# BL616/BL618 register map
Vendor: Bouffalo Lab; File version: 1.0
Registers are 32-bit, read-write, reset 0x0 unless marked. A register's access mark holds for its fields unless they carry their own. Offsets are from the block's base; [hi:lo] are bit positions; lines under a group give offsets from that group; {n}, {i} and the like mark numbered series.

## DMA — Direct Memory Access module
Base 0x2000C000
0x00 interrupt_state — ??
0x04 terminate_state — ??
0x08 terminate_clear — ??
0x0C error_state — ??
0x10 error_clear — ??
0x14 terminate_state_raw — ??
0x18 error_state_raw — ??
0x1C channel_state — ??
0x20 burst_request — ??
0x24 single_request — ??
0x28 last_burst_request — ??
0x2C last_single_request — ??
0x30 config — ??
  [0] function — Enable or disable DMA peripheral
0x34 synchronize — ??
{0x100+0x100*i} channel[{i}] (i=0..3) group — Direct Memory Access channel
  0x00 source — Source address
  0x04 destination — Destination address
  0x08 linked_list — Linked list buffer base address
    [31:0] base_address — Base address of first linked list item, must be aligned to 4 bytes
  0x0C control
  0x10 config — Configuration register
    [29:20] linked_list_counter — ??
    [17] halt — ??
    [16] active ro — ??
    [16] lock — ??
    [15] terminate_mask — Mask terminal count interrupt
    [14] error_mask — Mask error interrupt
    [13:11] flow_control — Set data direction for this channel
    [10:6] destination_peripheral — Set destination peripheral for this DMA channel
    [5:1] source_peripheral — Set source peripheral for this DMA channel
    [0] function — Enable or disable DMA channel

## PDS — Power-Down Sleep control
Base 0x2000E000
0xA00 touch_config — ??
0xA04 touch_channel — ??
0xA08 touch_process — ??
0xA0C touch_sleep — ??
0xA10 touch_delay — ??
{0xA14+4i} touch_force[{i}] (i=0..5) — ??
{0xA2C+4i} touch_voltage[{i}] (i=0..2) — ??
{0xA38+4i} touch_raw[{i}] (i=0..11) — ??
0xACC touch_interrupt_0 — ??
0xAD0 touch_interrupt_1 — ??

## HBN — Hibernate (Deep sleep) control
Base 0x2000F000
0x00 control — Miscellaneous control register
0x04 time_lo — Low bits of hibernate time
0x08 time_hi — High bits of hibernate time
0x0C rtc_time_lo — Low bits of Real-Time Clock time
0x10 rtc_time_hi — High bits of Real-Time Clock time
0x14 interrupt_mode — Hibernate interrupt contol
0x18 interrupt_state — Hibernate interrupt state
0x1C interrupt_clear — Clear hibernate interrupt
0x30 global — Global hibernate configuration
0x34 sram — Static Random-Access Memory hibernate control
0x200 rc32k — 32-kHz internal RC oscillator control
0x204 xtal32k — External crystal oscillator control
0x208 rtc_control_0 — Real-Time Clock control and reset register 0
0x20C rtc_control_1 — Real-Time Clock control and reset register 1

## AUDAC — Pulse-Width or Digital-to-Analog audio output
Base 0x20055000
0x00 clock — Clock control register
0x04 state — Peripheral state register
0x08 volume_0 — Volume control register 0
0x0C volume_1 — Volume control register 1
0x10 zero_signal — Zero signal detection
0x14 config — Delta-Sigma and mixer control
0x8C fifo_control — Controls audio output FIFO
0x90 fifo_state — Gets states of audio output FIFO
0x94 fifo_data — Writes data into audio output FIFO

## EMAC — Ethernet Media Access Control
Base 0x20070000
0x00 mode — Interface enables and configurations
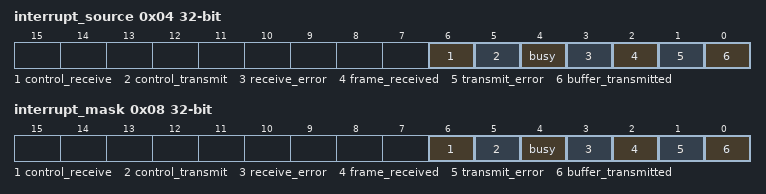
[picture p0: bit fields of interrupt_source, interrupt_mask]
0x04 interrupt_source write-1-clears
  [all] fields
    1=has_interrupt; 0=No interrupt occurred
  [6] control_receive — Control frame received interrupt state
  [5] control_transmit — Control frame transmitted interrupt state
  [4] busy — Lack of buffer interrupt state
  [3] receive_error — Receive error interrupt state
  [2] frame_received — Frame received interrupt state
  [1] transmit_error — Transmit error interrupt state
  [0] buffer_transmitted — Buffer transmitted interrupt state
0x08 interrupt_mask
  [all] fields
    1=Mask interrupt; 0=Unmask interrupt
  [6] control_receive — Control frame received interrupt mask
  [5] control_transmit — Control frame transmitted interrupt mask
  [4] busy — Lack of buffer interrupt mask
  [3] receive_error — Receive error interrupt mask
  [2] frame_received — Frame received interrupt mask
  [1] transmit_error — Transmit error interrupt mask
  [0] buffer_transmitted — Buffer transmitted interrupt mask
0x0C backed_gap — Back-to-back inter-packet gap register
0x10 non_backed_gap_1 — Non back-to-back inter-packet gap register 1
0x14 non_backed_gap_2 — Non back-to-back inter-packet gap register 2
0x18 frame_length — Minimum and maximum ethernet frame length
0x1C collision — Collision time window and maximum retries
0x20 transmit_buffer — Transmit buffer descriptor
0x24 flow_control — Control frame function register
0x28 mii_mode — MII clock divider and premable enable
0x2C mii_command — MII control data, read and scan state
0x30 mii_address — Physical layer bus address
0x34 control_write — Write data to MII physcial layer
0x38 control_read — Read data from MII physcial layer
0x3C mii_state — MII bus and link layer state
{0x40+4i} mac_address[{i}] (i=0..1) — Media Access Control address
{0x48+4i} hash[{i}] (i=0..1)
0x50 transmit_control

## USB — Universal Serial Bus host
Base 0x20072000
0x00 capability group — Host Controller Capability Registers
0x10 operation group — Host Controller Operational Registers
